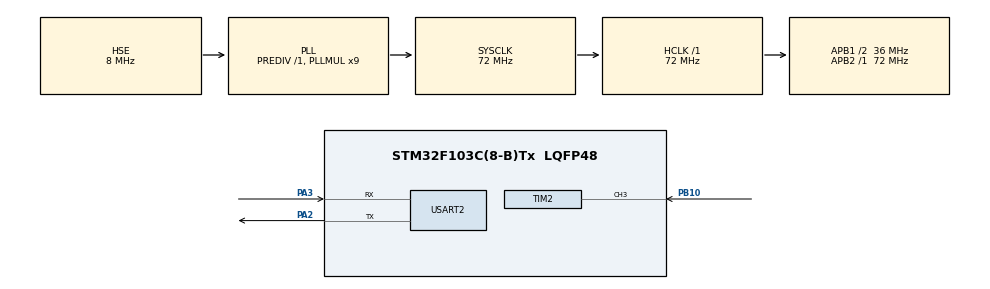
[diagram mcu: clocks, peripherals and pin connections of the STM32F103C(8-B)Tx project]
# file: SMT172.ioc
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Mcu.Family=STM32F1
Mcu.Name=STM32F103C(8-B)Tx
Mcu.Package=LQFP48
NVIC.PriorityGroup=NVIC_PRIORITYGROUP_4
NVIC.TIM2_IRQn=true\:0\:0\:false\:false\:true\:true\:true\:true
PA13.Mode=Serial_Wire
PA13.Signal=SYS_JTMS-SWDIO
PA14.Mode=Serial_Wire
PA14.Signal=SYS_JTCK-SWCLK
PA2.Mode=Asynchronous
PA2.Signal=USART2_TX
PA3.Mode=Asynchronous
PA3.Signal=USART2_RX
PB10.GPIO_PuPd=GPIO_PULLDOWN
PB10.Signal=S_TIM2_CH3
PD0-OSC_IN.Mode=HSE-External-Oscillator
PD0-OSC_IN.Signal=RCC_OSC_IN
PD1-OSC_OUT.Mode=HSE-External-Oscillator
PD1-OSC_OUT.Signal=RCC_OSC_OUT
ProjectManager.HeapSize=0x400
ProjectManager.StackSize=0x800
ProjectManager.TargetToolchain=MDK-ARM V5.32
RCC.AHBFreq_Value=72000000
RCC.APB1CLKDivider=RCC_HCLK_DIV2
RCC.APB1Freq_Value=36000000
RCC.APB1TimFreq_Value=72000000
RCC.APB2Freq_Value=72000000
RCC.APB2TimFreq_Value=72000000
RCC.HCLKFreq_Value=72000000
RCC.PLLMUL=RCC_PLL_MUL9
RCC.PLLSourceVirtual=RCC_PLLSOURCE_HSE
RCC.SYSCLKFreq_VALUE=72000000
RCC.SYSCLKSource=RCC_SYSCLKSOURCE_PLLCLK
RCC.USBFreq_Value=72000000
SH.S_TIM2_CH3.0=TIM2_CH3,Input_Capture3_from_TI3
TIM2.AutoReloadPreload=TIM_AUTORELOAD_PRELOAD_ENABLE
TIM2.Channel-Input_Capture3_from_TI3=TIM_CHANNEL_3
TIM2.ICPolarity_CH3=TIM_INPUTCHANNELPOLARITY_FALLING
USART2.VirtualMode=VM_ASYNC
VP_TIM2_VS_ClockSourceINT.Mode=Internal
board=custom

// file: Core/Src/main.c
/* USER CODE BEGIN Header */
/**
 ******************************************************************************
 * @file           : main.c
 * @brief          : Main program body
 ******************************************************************************
 * @attention
 *
 * Copyright (c) 2022 STMicroelectronics.
 * All rights reserved.
 *
 * This software is licensed under terms that can be found in the LICENSE file
 * in the root directory of this software component.
 * If no LICENSE file comes with this software, it is provided AS-IS.
 *
 ******************************************************************************
 */
/* USER CODE END Header */
#include "main.h"
#include "tim.h"
#include "usart.h"
#include "gpio.h"

/* USER CODE BEGIN Includes */
#include <stdio.h>
#include "SMT172.h"
/* USER CODE END Includes */

/* USER CODE BEGIN PV */
uint8_t Capture_Cnt = 0; //输入捕获计数
uint8_t Capture_Flag = 0;
uint8_t Capture_Flow = 0;

extern uint32_t Capture_Buf[129];
/* USER CODE END PV */

void SystemClock_Config(void);

int main(void)
{

  /* MCU Configuration--------------------------------------------------------*/

  /* Reset of all peripherals, Initializes the Flash interface and the Systick. */
  HAL_Init();

  /* Configure the system clock */
  SystemClock_Config();

  /* Initialize all configured peripherals */
  MX_GPIO_Init();
  MX_USART2_UART_Init();
  MX_TIM2_Init();

  /* Infinite loop */
  while (1)
  {

    /* USER CODE BEGIN 3 */
    printf("Temper:%f\n", Get_Temper());
    HAL_Delay(1000);
  }
  /* USER CODE END 3 */
}

void SystemClock_Config(void)
{
  RCC_OscInitTypeDef RCC_OscInitStruct = {0};
  RCC_ClkInitTypeDef RCC_ClkInitStruct = {0};

  /** Initializes the RCC Oscillators according to the specified parameters
   * in the RCC_OscInitTypeDef structure.
   */
  RCC_OscInitStruct.OscillatorType = RCC_OSCILLATORTYPE_HSE;
  RCC_OscInitStruct.HSEState = RCC_HSE_ON;
  RCC_OscInitStruct.HSEPredivValue = RCC_HSE_PREDIV_DIV1;
  RCC_OscInitStruct.HSIState = RCC_HSI_ON;
  RCC_OscInitStruct.PLL.PLLState = RCC_PLL_ON;
  RCC_OscInitStruct.PLL.PLLSource = RCC_PLLSOURCE_HSE;
  RCC_OscInitStruct.PLL.PLLMUL = RCC_PLL_MUL9;
  if (HAL_RCC_OscConfig(&RCC_OscInitStruct) != HAL_OK)
  {
    Error_Handler();
  }

  /** Initializes the CPU, AHB and APB buses clocks
   */
  RCC_ClkInitStruct.ClockType = RCC_CLOCKTYPE_HCLK | RCC_CLOCKTYPE_SYSCLK | RCC_CLOCKTYPE_PCLK1 | RCC_CLOCKTYPE_PCLK2;
  RCC_ClkInitStruct.SYSCLKSource = RCC_SYSCLKSOURCE_PLLCLK;
  RCC_ClkInitStruct.AHBCLKDivider = RCC_SYSCLK_DIV1;
  RCC_ClkInitStruct.APB1CLKDivider = RCC_HCLK_DIV2;
  RCC_ClkInitStruct.APB2CLKDivider = RCC_HCLK_DIV1;

  if (HAL_RCC_ClockConfig(&RCC_ClkInitStruct, FLASH_LATENCY_2) != HAL_OK)
  {
    Error_Handler();
  }
}

/* USER CODE BEGIN 4 */
//定时器输入捕获中断处理回调函数
void HAL_TIM_IC_CaptureCallback(TIM_HandleTypeDef *htim) //捕获中断发生时执行
{
  if (TIM2 == htim->Instance)
  {
    Capture_Buf[Capture_Cnt] = (HAL_TIM_ReadCapturedValue(&htim2, TIM_CHANNEL_3) + 65536 * Capture_Flow); //获取当前计数器的值
    if (Capture_Cnt >= 1 && (Capture_Buf[Capture_Cnt] < Capture_Buf[Capture_Cnt - 1]))
    {
      Capture_Buf[Capture_Cnt] += 65536;
      Capture_Flow++;
    }

    if (Capture_Cnt % 2 == 1)
    {
      __HAL_TIM_SET_CAPTUREPOLARITY(&htim2, TIM_CHANNEL_3, TIM_ICPOLARITY_FALLING); //配置TIM2通道3下降沿触发捕获
    }
    if (Capture_Cnt % 2 == 0) //当前进入中断是下降沿触发
    {
      __HAL_TIM_SET_CAPTUREPOLARITY(&htim2, TIM_CHANNEL_3, TIM_ICPOLARITY_RISING); //定时器2通道3设置为上升沿触发捕获
    }
    Capture_Cnt++;
    if (Capture_Cnt == 129)
    {
      __HAL_TIM_SET_CAPTUREPOLARITY(&htim2, TIM_CHANNEL_3, TIM_ICPOLARITY_FALLING); //配置TIM2通道3下降沿触发捕获
      HAL_TIM_IC_Stop_IT(&htim2, TIM_CHANNEL_3);                                    //关闭输入捕获
      Capture_Flag = 1;
      Capture_Cnt = 0;
      Capture_Flow = 0;
    }
  }
}

/* USER CODE END 4 */

void Error_Handler(void)
{
  __disable_irq();
  while (1)
  {
  }
}
